AUTOSAR XML (schema 3.1.2)
package /Components/SWC_ExMGslT2
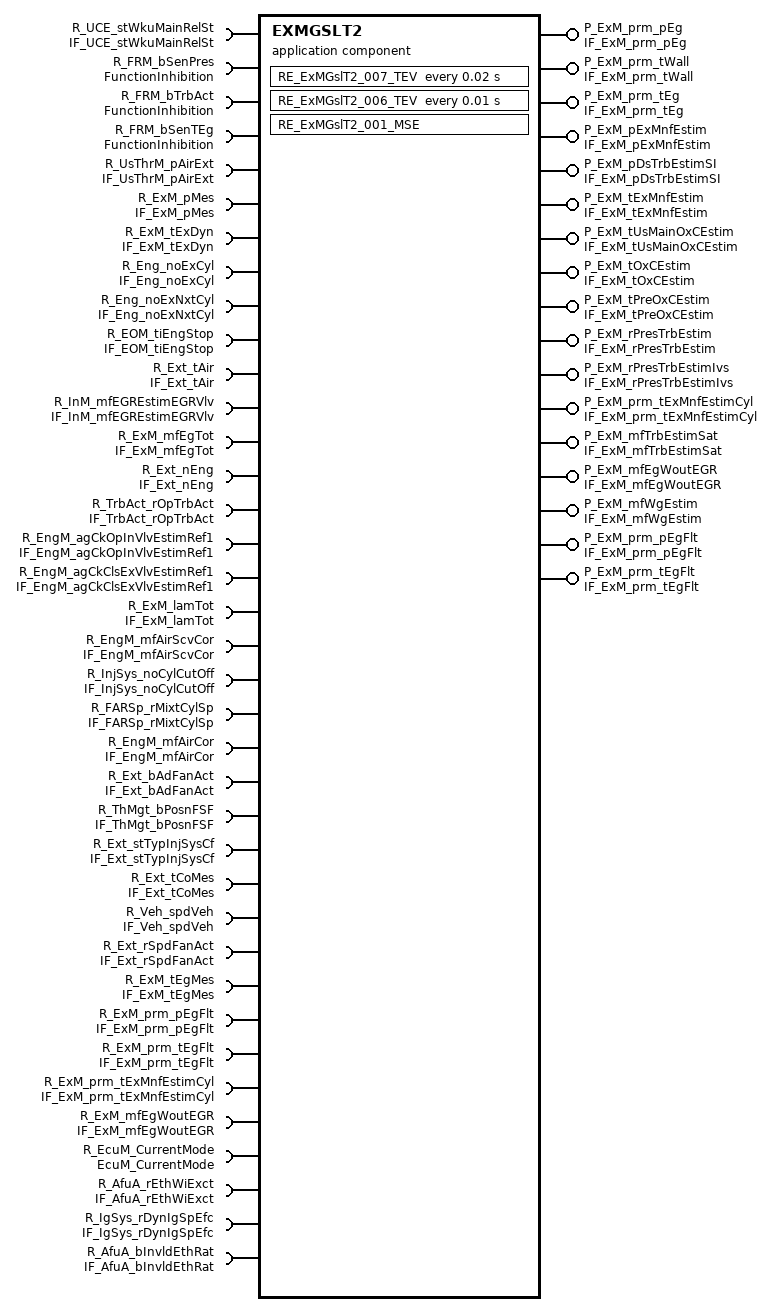
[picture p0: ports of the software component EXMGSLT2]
  application software component type EXMGSLT2  # ExMGslT2
    4 x require port:
      R_UCE_stWkuMainRelSt: required-interface=IF_UCE_stWkuMainRelSt
      R_FRM_bSenPres: required-interface=FunctionInhibition
      R_FRM_bTrbAct: required-interface=FunctionInhibition
      R_FRM_bSenTEg: required-interface=FunctionInhibition
    17 x provide port:
      P_ExM_prm_pEg: unqueued-sender-com-spec{data-element=ExM_prm_pEg, can-invalidate=false, init-value=rt_Array_UInt16_12InitValue}, provided-interface=IF_ExM_prm_pEg
      P_ExM_prm_tWall: unqueued-sender-com-spec{data-element=ExM_prm_tWall, can-invalidate=false, init-value=rt_Array_UInt16_12InitValue1}, provided-interface=IF_ExM_prm_tWall
      P_ExM_prm_tEg: unqueued-sender-com-spec{data-element=ExM_prm_tEg, can-invalidate=false, init-value=rt_Array_UInt16_12InitValue3}, provided-interface=IF_ExM_prm_tEg
      P_ExM_pExMnfEstim: unqueued-sender-com-spec{data-element=ExM_pExMnfEstim, can-invalidate=false, init-value=ConstantValue}, provided-interface=IF_ExM_pExMnfEstim
      P_ExM_pDsTrbEstimSI: unqueued-sender-com-spec{data-element=ExM_pDsTrbEstimSI, can-invalidate=false, init-value=ConstantValue5}, provided-interface=IF_ExM_pDsTrbEstimSI
      P_ExM_tExMnfEstim: unqueued-sender-com-spec{data-element=ExM_tExMnfEstim, can-invalidate=false, init-value=ConstantValue7}, provided-interface=IF_ExM_tExMnfEstim
      P_ExM_tUsMainOxCEstim: unqueued-sender-com-spec{data-element=ExM_tUsMainOxCEstim, can-invalidate=false, init-value=ConstantValue9}, provided-interface=IF_ExM_tUsMainOxCEstim
      P_ExM_tOxCEstim: unqueued-sender-com-spec{data-element=ExM_tOxCEstim, can-invalidate=false, init-value=SInt16InitValue}, provided-interface=IF_ExM_tOxCEstim
      P_ExM_tPreOxCEstim: unqueued-sender-com-spec{data-element=ExM_tPreOxCEstim, can-invalidate=false, init-value=SInt16InitValue11}, provided-interface=IF_ExM_tPreOxCEstim
      P_ExM_rPresTrbEstim: unqueued-sender-com-spec{data-element=ExM_rPresTrbEstim, can-invalidate=false, init-value=UInt16InitValue}, provided-interface=IF_ExM_rPresTrbEstim
      P_ExM_rPresTrbEstimIvs: unqueued-sender-com-spec{data-element=ExM_rPresTrbEstimIvs, can-invalidate=false, init-value=UInt16InitValue13}, provided-interface=IF_ExM_rPresTrbEstimIvs
      P_ExM_prm_tExMnfEstimCyl: unqueued-sender-com-spec{data-element=ExM_prm_tExMnfEstimCyl, can-invalidate=false, init-value=ArrayConstantValue}, provided-interface=IF_ExM_prm_tExMnfEstimCyl
      P_ExM_mfTrbEstimSat: unqueued-sender-com-spec{data-element=ExM_mfTrbEstimSat, can-invalidate=false, init-value=ConstantValue15}, provided-interface=IF_ExM_mfTrbEstimSat
      P_ExM_mfEgWoutEGR: unqueued-sender-com-spec{data-element=ExM_mfEgWoutEGR, can-invalidate=false, init-value=ConstantValue17}, provided-interface=IF_ExM_mfEgWoutEGR
      P_ExM_mfWgEstim: unqueued-sender-com-spec{data-element=ExM_mfWgEstim, can-invalidate=false, init-value=UInt16InitValue19}, provided-interface=IF_ExM_mfWgEstim
      P_ExM_prm_pEgFlt: unqueued-sender-com-spec{data-element=ExM_prm_pEgFlt, can-invalidate=false, init-value=rt_Array_UInt16_12InitValue21}, provided-interface=IF_ExM_prm_pEgFlt
      P_ExM_prm_tEgFlt: unqueued-sender-com-spec{data-element=ExM_prm_tEgFlt, can-invalidate=false, init-value=rt_Array_UInt16_12InitValue23}, provided-interface=IF_ExM_prm_tEgFlt
    33 x require port:
      R_UsThrM_pAirExt: unqueued-receiver-com-spec{data-element=UsThrM_pAirExt, init-value=ConstantValue25, resync-time=0}, required-interface=IF_UsThrM_pAirExt
      R_ExM_pMes: unqueued-receiver-com-spec{data-element=ExM_pMes, init-value=UInt16InitValue27, resync-time=0}, required-interface=IF_ExM_pMes
      R_ExM_tExDyn: unqueued-receiver-com-spec{data-element=ExM_tExDyn, init-value=ConstantValue29, resync-time=0}, required-interface=IF_ExM_tExDyn
      R_Eng_noExCyl: unqueued-receiver-com-spec{data-element=Eng_noExCyl, init-value=ConstantValue31, resync-time=0}, required-interface=IF_Eng_noExCyl
      R_Eng_noExNxtCyl: unqueued-receiver-com-spec{data-element=Eng_noExNxtCyl, init-value=ConstantValue33, resync-time=0}, required-interface=IF_Eng_noExNxtCyl
      R_EOM_tiEngStop: unqueued-receiver-com-spec{data-element=EOM_tiEngStop, init-value=ConstantValue35, resync-time=0}, required-interface=IF_EOM_tiEngStop
      R_Ext_tAir: unqueued-receiver-com-spec{data-element=Ext_tAir, init-value=ConstantValue37, resync-time=0}, required-interface=IF_Ext_tAir
      R_InM_mfEGREstimEGRVlv: unqueued-receiver-com-spec{data-element=InM_mfEGREstimEGRVlv, init-value=ConstantValue39, resync-time=0}, required-interface=IF_InM_mfEGREstimEGRVlv
      R_ExM_mfEgTot: unqueued-receiver-com-spec{data-element=ExM_mfEgTot, init-value=ConstantValue41, resync-time=0}, required-interface=IF_ExM_mfEgTot
      R_Ext_nEng: unqueued-receiver-com-spec{data-element=Ext_nEng, init-value=ConstantValue43, resync-time=0}, required-interface=IF_Ext_nEng
      R_TrbAct_rOpTrbAct: unqueued-receiver-com-spec{data-element=TrbAct_rOpTrbAct, init-value=UInt16InitValue45, resync-time=0}, required-interface=IF_TrbAct_rOpTrbAct
      R_EngM_agCkOpInVlvEstimRef1: unqueued-receiver-com-spec{data-element=EngM_agCkOpInVlvEstimRef1, init-value=ConstantValue47, resync-time=0}, required-interface=IF_EngM_agCkOpInVlvEstimRef1
      R_EngM_agCkClsExVlvEstimRef1: unqueued-receiver-com-spec{data-element=EngM_agCkClsExVlvEstimRef1, init-value=ConstantValue49, resync-time=0}, required-interface=IF_EngM_agCkClsExVlvEstimRef1
      R_ExM_lamTot: unqueued-receiver-com-spec{data-element=ExM_lamTot, init-value=ConstantValue51, resync-time=0}, required-interface=IF_ExM_lamTot
      R_EngM_mfAirScvCor: unqueued-receiver-com-spec{data-element=EngM_mfAirScvCor, init-value=ConstantValue53, resync-time=0}, required-interface=IF_EngM_mfAirScvCor
      R_InjSys_noCylCutOff: unqueued-receiver-com-spec{data-element=InjSys_noCylCutOff, init-value=ConstantValue55, resync-time=0}, required-interface=IF_InjSys_noCylCutOff
      R_FARSp_rMixtCylSp: unqueued-receiver-com-spec{data-element=FARSp_rMixtCylSp, init-value=ConstantValue57, resync-time=0}, required-interface=IF_FARSp_rMixtCylSp
      R_EngM_mfAirCor: unqueued-receiver-com-spec{data-element=EngM_mfAirCor, init-value=ConstantValue59, resync-time=0}, required-interface=IF_EngM_mfAirCor
      R_Ext_bAdFanAct: unqueued-receiver-com-spec{data-element=Ext_bAdFanAct, init-value=BooleanInitValue, resync-time=0}, required-interface=IF_Ext_bAdFanAct
      R_ThMgt_bPosnFSF: unqueued-receiver-com-spec{data-element=ThMgt_bPosnFSF, init-value=BooleanInitValue61, resync-time=0}, required-interface=IF_ThMgt_bPosnFSF
      R_Ext_stTypInjSysCf: unqueued-receiver-com-spec{data-element=Ext_stTypInjSysCf, init-value=UInt8InitValue, resync-time=0}, required-interface=IF_Ext_stTypInjSysCf
      R_Ext_tCoMes: unqueued-receiver-com-spec{data-element=Ext_tCoMes, init-value=ConstantValue63, resync-time=0}, required-interface=IF_Ext_tCoMes
      R_Veh_spdVeh: unqueued-receiver-com-spec{data-element=Veh_spdVeh, init-value=ConstantValue65, resync-time=0}, required-interface=IF_Veh_spdVeh
      R_Ext_rSpdFanAct: unqueued-receiver-com-spec{data-element=Ext_rSpdFanAct, init-value=UInt8InitValue67, resync-time=0}, required-interface=IF_Ext_rSpdFanAct
      R_ExM_tEgMes: unqueued-receiver-com-spec{data-element=ExM_tEgMes, init-value=UInt16InitValue69, resync-time=0}, required-interface=IF_ExM_tEgMes
      R_ExM_prm_pEgFlt: unqueued-receiver-com-spec{data-element=ExM_prm_pEgFlt, init-value=rt_Array_UInt16_12InitValue71, resync-time=0}, required-interface=IF_ExM_prm_pEgFlt
      R_ExM_prm_tEgFlt: unqueued-receiver-com-spec{data-element=ExM_prm_tEgFlt, init-value=rt_Array_UInt16_12InitValue73, resync-time=0}, required-interface=IF_ExM_prm_tEgFlt
      R_ExM_prm_tExMnfEstimCyl: unqueued-receiver-com-spec{data-element=ExM_prm_tExMnfEstimCyl, init-value=ArrayConstantValue, resync-time=0}, required-interface=IF_ExM_prm_tExMnfEstimCyl
      R_ExM_mfEgWoutEGR: unqueued-receiver-com-spec{data-element=ExM_mfEgWoutEGR, init-value=ConstantValue75, resync-time=0}, required-interface=IF_ExM_mfEgWoutEGR
      R_EcuM_CurrentMode: required-interface=EcuM_CurrentMode
      R_AfuA_rEthWiExct: unqueued-receiver-com-spec{data-element=AfuA_rEthWiExct, init-value=UInt8InitValue77, resync-time=0}, required-interface=IF_AfuA_rEthWiExct
      R_IgSys_rDynIgSpEfc: unqueued-receiver-com-spec{data-element=IgSys_rDynIgSpEfc, init-value=ConstantValue79, resync-time=0}, required-interface=IF_IgSys_rDynIgSpEfc
      R_AfuA_bInvldEthRat: unqueued-receiver-com-spec{data-element=AfuA_bInvldEthRat, init-value=ConstantValue1, resync-time=0}, required-interface=IF_AfuA_bInvldEthRat
  105 x constant specification:
    ArrayConstantValue
      value:
        array specification ArrayConstantValue: type=rt_Array_UInt16_6_m1
          6 x integer literal, all with type=DT_ExM_prm_tExMnfEstimCyl, value=0:
            Const
            Const{1..5}
    BooleanInitValue
      value:
        boolean literal BooleanInitValue: type=DT_Ext_bAdFanAct, value=false
    BooleanInitValue61
      value:
        boolean literal BooleanInitValue61: type=DT_ThMgt_bPosnFSF, value=false
    ConstantValue
      value:
        integer literal ConstantValue: type=DT_ExM_pExMnfEstim, value=0
    ConstantValue1
      value:
        boolean literal ConstantValue1: type=DT_AfuA_bInvldEthRat, value=false
    ConstantValue101
      value:
        real literal ConstantValue101: type=DT_ExM_prm_tWall_03_irv, value=0
    ConstantValue103
      value:
        real literal ConstantValue103: type=DT_ExM_prm_tWall_10_irv, value=0
    ConstantValue105
      value:
        real literal ConstantValue105: type=DT_ExM_prm_pEgRaw_07_irv, value=0
    ConstantValue109
      value:
        real literal ConstantValue109: type=DT_ExM_prm_tWall_08_irv, value=0
    ConstantValue115
      value:
        real literal ConstantValue115: type=DT_ExM_prm_pEgRaw_06_irv, value=0
    ConstantValue117
      value:
        real literal ConstantValue117: type=DT_ExM_prm_pEgRaw_05_irv, value=0
    ConstantValue119
      value:
        real literal ConstantValue119: type=DT_ExM_prm_tEgRaw_03_irv, value=0
    ConstantValue121
      value:
        real literal ConstantValue121: type=DT_ExM_prm_pEgRaw_03_irv, value=0
    ConstantValue123
      value:
        real literal ConstantValue123: type=DT_ExM_prm_tWall_09_irv, value=0
    ConstantValue125
      value:
        real literal ConstantValue125: type=DT_ExM_prm_tWall_01_irv, value=0
    ConstantValue127
      value:
        real literal ConstantValue127: type=DT_ExM_prm_tWall_06_irv, value=0
    ConstantValue129
      value:
        real literal ConstantValue129: type=DT_ExM_prm_tEgOxC_01_irv, value=0
    ConstantValue139
      value:
        real literal ConstantValue139: type=DT_ExM_mfWgEstim_irv, value=0
    ConstantValue141
      value:
        real literal ConstantValue141: type=DT_ExM_prm_tWall_04_irv, value=0
    ConstantValue145
      value:
        real literal ConstantValue145: type=DT_ExM_prm_tWall_11_irv, value=0
    ConstantValue147
      value:
        real literal ConstantValue147: type=DT_ExM_prm_tEgRaw_07_irv, value=0
    ConstantValue15
      value:
        integer literal ConstantValue15: type=DT_ExM_mfTrbEstimSat, value=0
    ConstantValue153
      value:
        real literal ConstantValue153: type=DT_ExM_prm_pEgRaw_01_irv, value=0
    ConstantValue155
      value:
        real literal ConstantValue155: type=DT_ExM_prm_pEgRaw_12_irv, value=0
    ConstantValue157
      value:
        real literal ConstantValue157: type=DT_ExM_prm_tEgRaw_06_irv, value=0
    ConstantValue159
      value:
        real literal ConstantValue159: type=DT_ExM_prm_tEgRaw_05_irv, value=0
    ConstantValue161
      value:
        real literal ConstantValue161: type=DT_ExM_prm_tWall_12_irv, value=0
    ConstantValue167
      value:
        real literal ConstantValue167: type=DT_ExM_prm_tEgRaw_04_irv, value=0
    ConstantValue169
      value:
        real literal ConstantValue169: type=DT_ExM_prm_tEgRaw_08_irv, value=0
    ConstantValue17
      value:
        integer literal ConstantValue17: type=DT_ExM_mfEgWoutEGR, value=0
    ConstantValue171
      value:
        real literal ConstantValue171: type=DT_ExM_mfTrbEstimSat_irv, value=0
    ConstantValue173
      value:
        real literal ConstantValue173: type=DT_ExM_prm_pEgRaw_08_irv, value=0
    ConstantValue177
      value:
        real literal ConstantValue177: type=DT_ExM_prm_tWall_02_irv, value=0
    ConstantValue179
      value:
        real literal ConstantValue179: type=DT_ExM_prm_tEgRaw_01_irv, value=0
    ConstantValue181
      value:
        real literal ConstantValue181: type=DT_ExM_prm_pEgRaw_11_irv, value=0
    ConstantValue185
      value:
        real literal ConstantValue185: type=DT_ExM_prm_tEgRaw_11_irv, value=0
    ConstantValue187
      value:
        real literal ConstantValue187: type=DT_ExM_prm_tEgRaw_02_irv, value=0
    ConstantValue189
      value:
        real literal ConstantValue189: type=DT_ExM_prm_pEgRaw_09_irv, value=0
    ConstantValue191
      value:
        real literal ConstantValue191: type=DT_ExM_prm_tEgOxC_02_irv, value=0
    ConstantValue193
      value:
        real literal ConstantValue193: type=DT_ExM_prm_tEgRaw_09_irv, value=0
    ConstantValue25
      value:
        integer literal ConstantValue25: type=DT_UsThrM_pAirExt, value=0
    ConstantValue29
      value:
        integer literal ConstantValue29: type=DT_ExM_tExDyn, value=0
    ConstantValue31
      value:
        integer literal ConstantValue31: type=DT_Eng_noExCyl, value=1
    ConstantValue33
      value:
        integer literal ConstantValue33: type=DT_Eng_noExNxtCyl, value=1
    ConstantValue35
      value:
        integer literal ConstantValue35: type=DT_EOM_tiEngStop, value=864000
    ConstantValue37
      value:
        integer literal ConstantValue37: type=DT_Ext_tAir, value=20
    ConstantValue39
      value:
        integer literal ConstantValue39: type=DT_InM_mfEGREstimEGRVlv, value=0
    ConstantValue41
      value:
        integer literal ConstantValue41: type=DT_ExM_mfEgTot, value=0
    ConstantValue43
      value:
        integer literal ConstantValue43: type=DT_Ext_nEng, value=0
    ConstantValue47
      value:
        integer literal ConstantValue47: type=DT_EngM_agCkOpInVlvEstimRef1, value=0
    ConstantValue49
      value:
        integer literal ConstantValue49: type=DT_EngM_agCkClsExVlvEstimRef1, value=0
    ConstantValue5
      value:
        integer literal ConstantValue5: type=DT_ExM_pDsTrbEstimSI, value=0
    ConstantValue51
      value:
        integer literal ConstantValue51: type=DT_ExM_lamTot, value=8192
    ConstantValue53
      value:
        integer literal ConstantValue53: type=DT_EngM_mfAirScvCor, value=0
    ConstantValue55
      value:
        integer literal ConstantValue55: type=DT_InjSys_noCylCutOff, value=0
    ConstantValue57
      value:
        integer literal ConstantValue57: type=DT_FARSp_rMixtCylSp, value=4096
    ConstantValue59
      value:
        integer literal ConstantValue59: type=DT_EngM_mfAirCor, value=0
    ConstantValue63
      value:
        integer literal ConstantValue63: type=DT_Ext_tCoMes, value=20
    ConstantValue65
      value:
        integer literal ConstantValue65: type=DT_Veh_spdVeh, value=0
    ConstantValue7
      value:
        integer literal ConstantValue7: type=DT_ExM_tExMnfEstim, value=4800
    ConstantValue75
      value:
        integer literal ConstantValue75: type=DT_ExM_mfEgWoutEGR, value=0
    ConstantValue79
      value:
        integer literal ConstantValue79: type=DT_IgSys_rDynIgSpEfc, value=0
    ConstantValue81
      value:
        real literal ConstantValue81: type=DT_ExM_prm_tEgOxC_03_irv, value=0
    ConstantValue83
      value:
        real literal ConstantValue83: type=DT_ExM_prm_tEgRaw_10_irv, value=0
    ConstantValue85
      value:
        real literal ConstantValue85: type=DT_ExM_prm_tWall_07_irv, value=0
    ConstantValue87
      value:
        real literal ConstantValue87: type=DT_ExM_prm_tWall_05_irv, value=0
    ConstantValue89
      value:
        real literal ConstantValue89: type=DT_ExM_prm_pEgRaw_10_irv, value=0
    ConstantValue9
      value:
        integer literal ConstantValue9: type=DT_ExM_tUsMainOxCEstim, value=0
    ConstantValue91
      value:
        real literal ConstantValue91: type=DT_ExM_prm_tEgRaw_12_irv, value=0
    ConstantValue93
      value:
        real literal ConstantValue93: type=DT_ExM_prm_pEgRaw_04_irv, value=0
    ConstantValue99
      value:
        real literal ConstantValue99: type=DT_ExM_prm_pEgRaw_02_irv, value=0
    rt_Array_UInt16_12InitValue
      value:
        array specification rt_Array_UInt16_12InitValue: type=rt_Array_UInt16_12_m2
          12 x integer literal, all with type=DT_ExM_prm_pEg, value=0:
            UInt16_{1..12}
    rt_Array_UInt16_12InitValue1
      value:
        array specification rt_Array_UInt16_12InitValue1: type=rt_Array_UInt16_12_m1
          12 x integer literal, all with type=DT_ExM_prm_tWall, value=0:
            UInt16_{1..12}
    rt_Array_UInt16_12InitValue21
      value:
        array specification rt_Array_UInt16_12InitValue21: type=rt_Array_UInt16_12_m3
          12 x integer literal, all with type=DT_ExM_prm_pEgFlt, value=0:
            UInt16_{1..12}
    rt_Array_UInt16_12InitValue23
      value:
        array specification rt_Array_UInt16_12InitValue23: type=rt_Array_UInt16_12_m5
          12 x integer literal, all with type=DT_ExM_prm_tEgFlt, value=0:
            UInt16_{1..12}
    rt_Array_UInt16_12InitValue3
      value:
        array specification rt_Array_UInt16_12InitValue3: type=rt_Array_UInt16_12_m0
          12 x integer literal, all with type=DT_ExM_prm_tEg, value=0:
            UInt16_{1..12}
    rt_Array_UInt16_12InitValue71
      value:
        array specification rt_Array_UInt16_12InitValue71: type=rt_Array_UInt16_12_m3
          12 x integer literal, all with type=DT_ExM_prm_pEgFlt, value=0:
            UInt16_{1..12}
    rt_Array_UInt16_12InitValue73
      value:
        array specification rt_Array_UInt16_12InitValue73: type=rt_Array_UInt16_12_m5
          12 x integer literal, all with type=DT_ExM_prm_tEgFlt, value=0:
            UInt16_{1..12}
    SInt16InitValue
      value:
        integer literal SInt16InitValue: type=DT_ExM_tOxCEstim, value=-55
    SInt16InitValue11
      value:
        integer literal SInt16InitValue11: type=DT_ExM_tPreOxCEstim, value=-55
    UInt16InitValue
      value:
        integer literal UInt16InitValue: type=DT_ExM_rPresTrbEstim, value=0
    UInt16InitValue13
      value:
        integer literal UInt16InitValue13: type=DT_ExM_rPresTrbEstimIvs, value=0
    UInt16InitValue19
      value:
        integer literal UInt16InitValue19: type=DT_ExM_mfWgEstim, value=0
    UInt16InitValue27
      value:
        integer literal UInt16InitValue27: type=DT_ExM_pMes, value=12662
    UInt16InitValue45
      value:
        integer literal UInt16InitValue45: type=DT_TrbAct_rOpTrbAct, value=0
    UInt16InitValue69
      value:
        integer literal UInt16InitValue69: type=DT_ExM_tEgMes, value=15264
    UInt8InitValue
      value:
        integer literal UInt8InitValue: type=DT_Ext_stTypInjSysCf, value=1
    UInt8InitValue107
      value:
        integer literal UInt8InitValue107: type=DT_ExM_prm_stElement_01_irv, value=0
    UInt8InitValue111
      value:
        integer literal UInt8InitValue111: type=DT_ExM_prm_stNbTypElement_08_irv, value=0
    UInt8InitValue113
      value:
        integer literal UInt8InitValue113: type=DT_ExM_prm_stNbTypElement_01_irv, value=0
    UInt8InitValue131
      value:
        integer literal UInt8InitValue131: type=DT_ExM_prm_stNbTypElement_05_irv, value=0
    UInt8InitValue133
      value:
        integer literal UInt8InitValue133: type=DT_ExM_prm_stNbTypElement_02_irv, value=0
    UInt8InitValue135
      value:
        integer literal UInt8InitValue135: type=DT_ExM_prm_stNbTypElement_06_irv, value=0
    UInt8InitValue137
      value:
        integer literal UInt8InitValue137: type=DT_ExM_prm_stElement_02_irv, value=0
    UInt8InitValue143
      value:
        integer literal UInt8InitValue143: type=DT_ExM_prm_stNbTypElement_03_irv, value=0
    UInt8InitValue149
      value:
        integer literal UInt8InitValue149: type=DT_ExM_prm_stElement_08_irv, value=0
    UInt8InitValue151
      value:
        integer literal UInt8InitValue151: type=DT_ExM_prm_stElement_04_irv, value=0
    UInt8InitValue163
      value:
        integer literal UInt8InitValue163: type=DT_ExM_prm_stElement_06_irv, value=0
    UInt8InitValue165
      value:
        integer literal UInt8InitValue165: type=DT_ExM_prm_stNbTypElement_07_irv, value=0
    UInt8InitValue175
      value:
        integer literal UInt8InitValue175: type=DT_ExM_prm_stElement_07_irv, value=0
    UInt8InitValue183
      value:
        integer literal UInt8InitValue183: type=DT_ExM_prm_stNbTypElement_04_irv, value=0
    UInt8InitValue67
      value:
        integer literal UInt8InitValue67: type=DT_Ext_rSpdFanAct, value=0
    UInt8InitValue77
      value:
        integer literal UInt8InitValue77: type=DT_AfuA_rEthWiExct, value=0
    UInt8InitValue95
      value:
        integer literal UInt8InitValue95: type=DT_ExM_prm_stElement_03_irv, value=0
    UInt8InitValue97
      value:
        integer literal UInt8InitValue97: type=DT_ExM_prm_stElement_05_irv, value=0
  internal behavior IB_ExMGslT2: component=EXMGSLT2
    timing event EV_ExMGslT2_007_TEV: mode-dependency=dependent-on-mode=[R_UCE_stWkuMainRelSt.RCD_stWkuMainRelSt.PreMainWakeUp, R_UCE_stWkuMainRelSt.RCD_stWkuMainRelSt.PostMainWakeUp, R_UCE_stWkuMainRelSt.RCD_stWkuMainRelSt.Invalid], start-on-event=RE_ExMGslT2_007_TEV, period=0.02
    timing event EV_ExMGslT2_006_TEV: mode-dependency=dependent-on-mode=[R_UCE_stWkuMainRelSt.RCD_stWkuMainRelSt.PreMainWakeUp, R_UCE_stWkuMainRelSt.RCD_stWkuMainRelSt.PostMainWakeUp, R_UCE_stWkuMainRelSt.RCD_stWkuMainRelSt.Invalid], start-on-event=RE_ExMGslT2_006_TEV, period=0.01
    mode switch event EV_ExMGslT2_001_MSE: start-on-event=RE_ExMGslT2_001_MSE, activation=ENTRY, mode=R_EcuM_CurrentMode.currentMode.RUN
    57 x inter runnable variable, all with sw-calibration-access=READ-WRITE, communication-approach=EXPLICIT:
      ExM_prm_tWall_05_irv: type=DT_ExM_prm_tWall_05_irv, init-value=ConstantValue87
      ExM_prm_tWall_02_irv: type=DT_ExM_prm_tWall_02_irv, init-value=ConstantValue177
      ExM_prm_pEgRaw_11_irv: type=DT_ExM_prm_pEgRaw_11_irv, init-value=ConstantValue181
      ExM_prm_stNbTypElement_05_irv: type=DT_ExM_prm_stNbTypElement_05_irv, init-value=UInt8InitValue131
      ExM_prm_stNbTypElement_02_irv: type=DT_ExM_prm_stNbTypElement_02_irv, init-value=UInt8InitValue133
      ExM_mfWgEstim_irv: type=DT_ExM_mfWgEstim_irv, init-value=ConstantValue139
      ExM_prm_pEgRaw_08_irv: type=DT_ExM_prm_pEgRaw_08_irv, init-value=ConstantValue173
      ExM_prm_tEgRaw_03_irv: type=DT_ExM_prm_tEgRaw_03_irv, init-value=ConstantValue119
      ExM_prm_pEgRaw_12_irv: type=DT_ExM_prm_pEgRaw_12_irv, init-value=ConstantValue155
      ExM_prm_tWall_09_irv: type=DT_ExM_prm_tWall_09_irv, init-value=ConstantValue123
      ExM_mfTrbEstimSat_irv: type=DT_ExM_mfTrbEstimSat_irv, init-value=ConstantValue171
      ExM_prm_tWall_01_irv: type=DT_ExM_prm_tWall_01_irv, init-value=ConstantValue125
      ExM_prm_stElement_02_irv: type=DT_ExM_prm_stElement_02_irv, init-value=UInt8InitValue137
      ExM_prm_stNbTypElement_06_irv: type=DT_ExM_prm_stNbTypElement_06_irv, init-value=UInt8InitValue135
      ExM_prm_tEgRaw_10_irv: type=DT_ExM_prm_tEgRaw_10_irv, init-value=ConstantValue83
      ExM_prm_tWall_12_irv: type=DT_ExM_prm_tWall_12_irv, init-value=ConstantValue161
      ExM_prm_tEgOxC_02_irv: type=DT_ExM_prm_tEgOxC_02_irv, init-value=ConstantValue191
      ExM_prm_tEgRaw_04_irv: type=DT_ExM_prm_tEgRaw_04_irv, init-value=ConstantValue167
      ExM_prm_stElement_04_irv: type=DT_ExM_prm_stElement_04_irv, init-value=UInt8InitValue151
      ExM_prm_tEgRaw_09_irv: type=DT_ExM_prm_tEgRaw_09_irv, init-value=ConstantValue193
      ExM_prm_stElement_05_irv: type=DT_ExM_prm_stElement_05_irv, init-value=UInt8InitValue97
      ExM_prm_stElement_07_irv: type=DT_ExM_prm_stElement_07_irv, init-value=UInt8InitValue175
      ExM_prm_tWall_04_irv: type=DT_ExM_prm_tWall_04_irv, init-value=ConstantValue141
      ExM_prm_stElement_01_irv: type=DT_ExM_prm_stElement_01_irv, init-value=UInt8InitValue107
      ExM_prm_tEgRaw_07_irv: type=DT_ExM_prm_tEgRaw_07_irv, init-value=ConstantValue147
      ExM_prm_tWall_07_irv: type=DT_ExM_prm_tWall_07_irv, init-value=ConstantValue85
      ExM_prm_stNbTypElement_04_irv: type=DT_ExM_prm_stNbTypElement_04_irv, init-value=UInt8InitValue183
      ExM_prm_tEgRaw_01_irv: type=DT_ExM_prm_tEgRaw_01_irv, init-value=ConstantValue179
      ExM_prm_stElement_03_irv: type=DT_ExM_prm_stElement_03_irv, init-value=UInt8InitValue95
      ExM_prm_tEgRaw_05_irv: type=DT_ExM_prm_tEgRaw_05_irv, init-value=ConstantValue159
      ExM_prm_pEgRaw_06_irv: type=DT_ExM_prm_pEgRaw_06_irv, init-value=ConstantValue115
      ExM_prm_pEgRaw_09_irv: type=DT_ExM_prm_pEgRaw_09_irv, init-value=ConstantValue189
      ExM_prm_tWall_06_irv: type=DT_ExM_prm_tWall_06_irv, init-value=ConstantValue127
      ExM_prm_stNbTypElement_08_irv: type=DT_ExM_prm_stNbTypElement_08_irv, init-value=UInt8InitValue111
      ExM_prm_stElement_06_irv: type=DT_ExM_prm_stElement_06_irv, init-value=UInt8InitValue163
      ExM_prm_pEgRaw_04_irv: type=DT_ExM_prm_pEgRaw_04_irv, init-value=ConstantValue93
      ExM_prm_tEgRaw_06_irv: type=DT_ExM_prm_tEgRaw_06_irv, init-value=ConstantValue157
      ExM_prm_tWall_11_irv: type=DT_ExM_prm_tWall_11_irv, init-value=ConstantValue145
      ExM_prm_tEgRaw_12_irv: type=DT_ExM_prm_tEgRaw_12_irv, init-value=ConstantValue91
      ExM_prm_stNbTypElement_07_irv: type=DT_ExM_prm_stNbTypElement_07_irv, init-value=UInt8InitValue165
      ExM_prm_tEgRaw_11_irv: type=DT_ExM_prm_tEgRaw_11_irv, init-value=ConstantValue185
      ExM_prm_tEgRaw_08_irv: type=DT_ExM_prm_tEgRaw_08_irv, init-value=ConstantValue169
      ExM_prm_pEgRaw_02_irv: type=DT_ExM_prm_pEgRaw_02_irv, init-value=ConstantValue99
      ExM_prm_stNbTypElement_01_irv: type=DT_ExM_prm_stNbTypElement_01_irv, init-value=UInt8InitValue113
      ExM_prm_tWall_10_irv: type=DT_ExM_prm_tWall_10_irv, init-value=ConstantValue103
      ExM_prm_tEgOxC_03_irv: type=DT_ExM_prm_tEgOxC_03_irv, init-value=ConstantValue81
      ExM_prm_tWall_03_irv: type=DT_ExM_prm_tWall_03_irv, init-value=ConstantValue101
      ExM_prm_stElement_08_irv: type=DT_ExM_prm_stElement_08_irv, init-value=UInt8InitValue149
      ExM_prm_stNbTypElement_03_irv: type=DT_ExM_prm_stNbTypElement_03_irv, init-value=UInt8InitValue143
      ExM_prm_tEgRaw_02_irv: type=DT_ExM_prm_tEgRaw_02_irv, init-value=ConstantValue187
      ExM_prm_pEgRaw_01_irv: type=DT_ExM_prm_pEgRaw_01_irv, init-value=ConstantValue153
      ExM_prm_pEgRaw_10_irv: type=DT_ExM_prm_pEgRaw_10_irv, init-value=ConstantValue89
      ExM_prm_pEgRaw_05_irv: type=DT_ExM_prm_pEgRaw_05_irv, init-value=ConstantValue117
      ExM_prm_pEgRaw_07_irv: type=DT_ExM_prm_pEgRaw_07_irv, init-value=ConstantValue105
      ExM_prm_pEgRaw_03_irv: type=DT_ExM_prm_pEgRaw_03_irv, init-value=ConstantValue121
      ExM_prm_tEgOxC_01_irv: type=DT_ExM_prm_tEgOxC_01_irv, init-value=ConstantValue129
      ExM_prm_tWall_08_irv: type=DT_ExM_prm_tWall_08_irv, init-value=ConstantValue109
    runnable RE_ExMGslT2_001_MSE: written-variable=[ExM_prm_tWall_07_irv, ExM_prm_stNbTypElement_07_irv, ExM_prm_tEgRaw_05_irv, ExM_prm_pEgRaw_04_irv, ExM_prm_stNbTypElement_04_irv, ExM_prm_pEgRaw_09_irv, ExM_prm_tWall_08_irv, ExM_prm_tEgRaw_02_irv, ExM_prm_stNbTypElement_01_irv, ExM_prm_tEgRaw_01_irv, ExM_prm_tWall_11_irv, ExM_prm_tEgOxC_03_irv, ExM_prm_stElement_05_irv, ExM_prm_tEgRaw_09_irv, ExM_prm_stElement_08_irv, ExM_mfTrbEstimSat_irv, ExM_prm_tEgRaw_03_irv, ExM_prm_tEgRaw_11_irv, ExM_prm_pEgRaw_10_irv, ExM_prm_pEgRaw_11_irv, ExM_prm_tEgOxC_02_irv, ExM_prm_stElement_04_irv, ExM_prm_stElement_06_irv, ExM_prm_tWall_04_irv, ExM_prm_tWall_09_irv, ExM_prm_pEgRaw_02_irv, ExM_mfWgEstim_irv, ExM_prm_tEgRaw_07_irv, ExM_prm_stElement_02_irv, ExM_prm_stNbTypElement_06_irv, ExM_prm_tEgRaw_12_irv, ExM_prm_stNbTypElement_08_irv, ExM_prm_pEgRaw_03_irv, ExM_prm_pEgRaw_08_irv, ExM_prm_tWall_01_irv, ExM_prm_stElement_01_irv, ExM_prm_tWall_05_irv, ExM_prm_pEgRaw_12_irv, ExM_prm_stNbTypElement_02_irv, ExM_prm_pEgRaw_07_irv, ExM_prm_stNbTypElement_03_irv, ExM_prm_pEgRaw_05_irv, ExM_prm_tWall_12_irv, ExM_prm_stElement_07_irv, ExM_prm_stElement_03_irv, ExM_prm_tEgRaw_04_irv, ExM_prm_tEgRaw_10_irv, ExM_prm_tEgRaw_06_irv, ExM_prm_tEgRaw_08_irv, ExM_prm_stNbTypElement_05_irv, ExM_prm_tWall_02_irv, ExM_prm_pEgRaw_06_irv, ExM_prm_tEgOxC_01_irv, ExM_prm_tWall_03_irv, ExM_prm_pEgRaw_01_irv, ExM_prm_tWall_06_irv, ExM_prm_tWall_10_irv]
      data receive point dr_Ext_tAir: data-element=R_Ext_tAir.Ext_tAir
      data receive point dr_EOM_tiEngStop: data-element=R_EOM_tiEngStop.EOM_tiEngStop
      data receive point dr_UsThrM_pAirExt: data-element=R_UsThrM_pAirExt.UsThrM_pAirExt
      17 x data send point:
        ds_ExM_mfWgEstim: data-element=P_ExM_mfWgEstim.ExM_mfWgEstim
        ds_ExM_prm_tExMnfEstimCyl: data-element=P_ExM_prm_tExMnfEstimCyl.ExM_prm_tExMnfEstimCyl
        ds_ExM_rPresTrbEstimIvs: data-element=P_ExM_rPresTrbEstimIvs.ExM_rPresTrbEstimIvs
        ds_ExM_tPreOxCEstim: data-element=P_ExM_tPreOxCEstim.ExM_tPreOxCEstim
        ds_ExM_tOxCEstim: data-element=P_ExM_tOxCEstim.ExM_tOxCEstim
        ds_ExM_prm_pEgFlt: data-element=P_ExM_prm_pEgFlt.ExM_prm_pEgFlt
        ds_ExM_prm_tEg: data-element=P_ExM_prm_tEg.ExM_prm_tEg
        ds_ExM_prm_tWall: data-element=P_ExM_prm_tWall.ExM_prm_tWall
        ds_ExM_pExMnfEstim: data-element=P_ExM_pExMnfEstim.ExM_pExMnfEstim
        ds_ExM_mfTrbEstimSat: data-element=P_ExM_mfTrbEstimSat.ExM_mfTrbEstimSat
        ds_ExM_prm_tEgFlt: data-element=P_ExM_prm_tEgFlt.ExM_prm_tEgFlt
        ds_ExM_tExMnfEstim: data-element=P_ExM_tExMnfEstim.ExM_tExMnfEstim
        ds_ExM_pDsTrbEstimSI: data-element=P_ExM_pDsTrbEstimSI.ExM_pDsTrbEstimSI
        ds_ExM_tUsMainOxCEstim: data-element=P_ExM_tUsMainOxCEstim.ExM_tUsMainOxCEstim
        ds_ExM_mfEgWoutEGR: data-element=P_ExM_mfEgWoutEGR.ExM_mfEgWoutEGR
        ds_ExM_rPresTrbEstim: data-element=P_ExM_rPresTrbEstim.ExM_rPresTrbEstim
        ds_ExM_prm_pEg: data-element=P_ExM_prm_pEg.ExM_prm_pEg
    runnable RE_ExMGslT2_007_TEV: read-variable=[ExM_prm_stNbTypElement_03_irv, ExM_prm_tEgRaw_12_irv, ExM_prm_stElement_06_irv, ExM_prm_pEgRaw_02_irv, ExM_prm_tWall_07_irv, ExM_prm_stNbTypElement_07_irv, ExM_prm_tEgOxC_03_irv, ExM_prm_pEgRaw_05_irv, ExM_prm_stNbTypElement_05_irv, ExM_prm_stElement_01_irv, ExM_prm_pEgRaw_09_irv, ExM_prm_tEgRaw_01_irv, ExM_prm_pEgRaw_11_irv, ExM_prm_pEgRaw_08_irv, ExM_prm_tWall_06_irv, ExM_prm_pEgRaw_12_irv, ExM_prm_tEgRaw_02_irv, ExM_prm_stNbTypElement_08_irv, ExM_prm_tEgRaw_05_irv, ExM_prm_tWall_11_irv, ExM_mfWgEstim_irv, ExM_prm_tEgRaw_07_irv, ExM_prm_tWall_04_irv, ExM_prm_tEgRaw_04_irv, ExM_prm_pEgRaw_01_irv, ExM_prm_pEgRaw_04_irv, ExM_prm_stNbTypElement_06_irv, ExM_prm_stNbTypElement_04_irv, ExM_prm_stElement_05_irv, ExM_prm_tWall_01_irv, ExM_prm_tEgOxC_02_irv, ExM_prm_stNbTypElement_01_irv, ExM_prm_tWall_08_irv, ExM_prm_stElement_08_irv, ExM_prm_tEgRaw_08_irv, ExM_prm_stElement_07_irv, ExM_prm_tEgRaw_11_irv, ExM_prm_pEgRaw_10_irv, ExM_prm_stElement_02_irv, ExM_prm_tEgOxC_01_irv, ExM_mfTrbEstimSat_irv, ExM_prm_tEgRaw_06_irv, ExM_prm_stNbTypElement_02_irv, ExM_prm_tWall_03_irv, ExM_prm_pEgRaw_03_irv, ExM_prm_tWall_10_irv, ExM_prm_tWall_05_irv, ExM_prm_tWall_02_irv, ExM_prm_tEgRaw_10_irv, ExM_prm_tWall_12_irv, ExM_prm_pEgRaw_06_irv, ExM_prm_stElement_03_irv, ExM_prm_pEgRaw_07_irv, ExM_prm_tWall_09_irv, ExM_prm_tEgRaw_09_irv, ExM_prm_stElement_04_irv, ExM_prm_tEgRaw_03_irv], written-variable=[ExM_prm_tEgRaw_12_irv, ExM_prm_tWall_07_irv, ExM_prm_tEgOxC_03_irv, ExM_prm_tEgRaw_01_irv, ExM_prm_tWall_06_irv, ExM_prm_tEgRaw_02_irv, ExM_prm_tEgRaw_05_irv, ExM_prm_tWall_11_irv, ExM_prm_tEgRaw_07_irv, ExM_prm_tWall_04_irv, ExM_prm_tEgRaw_04_irv, ExM_prm_tWall_01_irv, ExM_prm_tEgOxC_02_irv, ExM_prm_tWall_08_irv, ExM_prm_tEgRaw_08_irv, ExM_prm_tEgRaw_11_irv, ExM_prm_tEgOxC_01_irv, ExM_prm_tEgRaw_06_irv, ExM_prm_tWall_03_irv, ExM_prm_tWall_10_irv, ExM_prm_tWall_05_irv, ExM_prm_tWall_02_irv, ExM_prm_tEgRaw_10_irv, ExM_prm_tWall_12_irv, ExM_prm_tWall_09_irv, ExM_prm_tEgRaw_09_irv, ExM_prm_tEgRaw_03_irv]
      23 x data receive point:
        dr_ExM_lamTot: data-element=R_ExM_lamTot.ExM_lamTot
        dr_ExM_tExDyn: data-element=R_ExM_tExDyn.ExM_tExDyn
        dr_Eng_noExCyl: data-element=R_Eng_noExCyl.Eng_noExCyl
        dr_ExM_prm_tEgFlt: data-element=R_ExM_prm_tEgFlt.ExM_prm_tEgFlt
        dr_ThMgt_bPosnFSF: data-element=R_ThMgt_bPosnFSF.ThMgt_bPosnFSF
        dr_IgSys_rDynIgSpEfc: data-element=R_IgSys_rDynIgSpEfc.IgSys_rDynIgSpEfc
        dr_ExM_tEgMes: data-element=R_ExM_tEgMes.ExM_tEgMes
        dr_Ext_tCoMes: data-element=R_Ext_tCoMes.Ext_tCoMes
        dr_ExM_prm_tExMnfEstimCyl: data-element=R_ExM_prm_tExMnfEstimCyl.ExM_prm_tExMnfEstimCyl
        dr_Ext_bAdFanAct: data-element=R_Ext_bAdFanAct.Ext_bAdFanAct
        dr_EngM_mfAirCor: data-element=R_EngM_mfAirCor.EngM_mfAirCor
        dr_Ext_tAir: data-element=R_Ext_tAir.Ext_tAir
        dr_Ext_nEng: data-element=R_Ext_nEng.Ext_nEng
        dr_Eng_noExNxtCyl: data-element=R_Eng_noExNxtCyl.Eng_noExNxtCyl
        dr_AfuA_bInvldEthRat: data-element=R_AfuA_bInvldEthRat.AfuA_bInvldEthRat
        dr_EngM_mfAirScvCor: data-element=R_EngM_mfAirScvCor.EngM_mfAirScvCor
        dr_FARSp_rMixtCylSp: data-element=R_FARSp_rMixtCylSp.FARSp_rMixtCylSp
        dr_Veh_spdVeh: data-element=R_Veh_spdVeh.Veh_spdVeh
        dr_Ext_stTypInjSysCf: data-element=R_Ext_stTypInjSysCf.Ext_stTypInjSysCf
        dr_ExM_mfEgWoutEGR: data-element=R_ExM_mfEgWoutEGR.ExM_mfEgWoutEGR
        dr_Ext_rSpdFanAct: data-element=R_Ext_rSpdFanAct.Ext_rSpdFanAct
        dr_InjSys_noCylCutOff: data-element=R_InjSys_noCylCutOff.InjSys_noCylCutOff
        dr_AfuA_rEthWiExct: data-element=R_AfuA_rEthWiExct.AfuA_rEthWiExct
      8 x data send point:
        ds_ExM_tUsMainOxCEstim: data-element=P_ExM_tUsMainOxCEstim.ExM_tUsMainOxCEstim
        ds_ExM_prm_tEg: data-element=P_ExM_prm_tEg.ExM_prm_tEg
        ds_ExM_tOxCEstim: data-element=P_ExM_tOxCEstim.ExM_tOxCEstim
        ds_ExM_prm_tEgFlt: data-element=P_ExM_prm_tEgFlt.ExM_prm_tEgFlt
        ds_ExM_tPreOxCEstim: data-element=P_ExM_tPreOxCEstim.ExM_tPreOxCEstim
        ds_ExM_tExMnfEstim: data-element=P_ExM_tExMnfEstim.ExM_tExMnfEstim
        ds_ExM_prm_tWall: data-element=P_ExM_prm_tWall.ExM_prm_tWall
        ds_ExM_prm_tExMnfEstimCyl: data-element=P_ExM_prm_tExMnfEstimCyl.ExM_prm_tExMnfEstimCyl
      sync call ssp_FRM_bSenTEg: operation=R_FRM_bSenTEg.GetFunctionPermission
    runnable RE_ExMGslT2_006_TEV: read-variable=[ExM_prm_stElement_04_irv, ExM_prm_stNbTypElement_06_irv, ExM_prm_pEgRaw_06_irv, ExM_prm_stNbTypElement_02_irv, ExM_prm_stElement_05_irv, ExM_prm_pEgRaw_11_irv, ExM_prm_tEgRaw_02_irv, ExM_prm_stNbTypElement_05_irv, ExM_prm_stNbTypElement_01_irv, ExM_prm_stElement_06_irv, ExM_mfWgEstim_irv, ExM_prm_tEgRaw_05_irv, ExM_prm_stElement_01_irv, ExM_prm_tEgRaw_11_irv, ExM_prm_tEgRaw_04_irv, ExM_prm_tEgRaw_01_irv, ExM_prm_stElement_02_irv, ExM_prm_tEgRaw_09_irv, ExM_prm_pEgRaw_08_irv, ExM_prm_stElement_07_irv, ExM_prm_stNbTypElement_08_irv, ExM_prm_pEgRaw_05_irv, ExM_prm_stNbTypElement_07_irv, ExM_prm_tEgRaw_08_irv, ExM_prm_tEgRaw_03_irv, ExM_prm_pEgRaw_10_irv, ExM_prm_stElement_08_irv, ExM_prm_tEgRaw_07_irv, ExM_prm_pEgRaw_07_irv, ExM_prm_stElement_03_irv, ExM_prm_stNbTypElement_03_irv, ExM_prm_pEgRaw_03_irv, ExM_prm_tEgRaw_10_irv, ExM_prm_tEgRaw_12_irv, ExM_prm_pEgRaw_09_irv, ExM_mfTrbEstimSat_irv, ExM_prm_pEgRaw_12_irv, ExM_prm_pEgRaw_04_irv, ExM_prm_stNbTypElement_04_irv, ExM_prm_tEgRaw_06_irv, ExM_prm_pEgRaw_01_irv, ExM_prm_pEgRaw_02_irv], written-variable=[ExM_prm_pEgRaw_06_irv, ExM_prm_pEgRaw_11_irv, ExM_mfWgEstim_irv, ExM_prm_pEgRaw_08_irv, ExM_prm_pEgRaw_05_irv, ExM_prm_pEgRaw_10_irv, ExM_prm_pEgRaw_07_irv, ExM_prm_pEgRaw_03_irv, ExM_prm_pEgRaw_09_irv, ExM_mfTrbEstimSat_irv, ExM_prm_pEgRaw_12_irv, ExM_prm_pEgRaw_04_irv, ExM_prm_pEgRaw_01_irv, ExM_prm_pEgRaw_02_irv]
      10 x data receive point:
        dr_ExM_mfEgTot: data-element=R_ExM_mfEgTot.ExM_mfEgTot
        dr_ExM_prm_pEgFlt: data-element=R_ExM_prm_pEgFlt.ExM_prm_pEgFlt
        dr_Ext_nEng: data-element=R_Ext_nEng.Ext_nEng
        dr_InM_mfEGREstimEGRVlv: data-element=R_InM_mfEGREstimEGRVlv.InM_mfEGREstimEGRVlv
        dr_EngM_agCkOpInVlvEstimRef1: data-element=R_EngM_agCkOpInVlvEstimRef1.EngM_agCkOpInVlvEstimRef1
        dr_UsThrM_pAirExt: data-element=R_UsThrM_pAirExt.UsThrM_pAirExt
        dr_TrbAct_rOpTrbAct: data-element=R_TrbAct_rOpTrbAct.TrbAct_rOpTrbAct
        dr_ExM_pMes: data-element=R_ExM_pMes.ExM_pMes
        dr_EngM_agCkClsExVlvEstimRef1: data-element=R_EngM_agCkClsExVlvEstimRef1.EngM_agCkClsExVlvEstimRef1
        dr_ExM_mfEgWoutEGR: data-element=R_ExM_mfEgWoutEGR.ExM_mfEgWoutEGR
      8 x data send point:
        ds_ExM_pDsTrbEstimSI: data-element=P_ExM_pDsTrbEstimSI.ExM_pDsTrbEstimSI
        ds_ExM_rPresTrbEstimIvs: data-element=P_ExM_rPresTrbEstimIvs.ExM_rPresTrbEstimIvs
        ds_ExM_mfTrbEstimSat: data-element=P_ExM_mfTrbEstimSat.ExM_mfTrbEstimSat
        ds_ExM_rPresTrbEstim: data-element=P_ExM_rPresTrbEstim.ExM_rPresTrbEstim
        ds_ExM_mfWgEstim: data-element=P_ExM_mfWgEstim.ExM_mfWgEstim
        ds_ExM_prm_pEg: data-element=P_ExM_prm_pEg.ExM_prm_pEg
        ds_ExM_prm_pEgFlt: data-element=P_ExM_prm_pEgFlt.ExM_prm_pEgFlt
        ds_ExM_pExMnfEstim: data-element=P_ExM_pExMnfEstim.ExM_pExMnfEstim
      sync call ssp_FRM_bTrbAct: operation=R_FRM_bTrbAct.GetFunctionPermission
      sync call ssp_FRM_bSenPres: operation=R_FRM_bSenPres.GetFunctionPermission
  swc implementation Imp_ExMGslT2: code-generator=Real-Time Workshop Embedded Coder 5.5 (R2010a) 25-Jan-2010, programming-language=C, behavior=IB_ExMGslT2
    code-descriptors:
      code CodeDescriptor: type=SRC
        12 x xfile:
          ExMGslT2_types_h: url=ExMGslT2_types.h
          ExMGslT2_MemMap_h: url=ExMGslT2_MemMap.h
          ExMGslT2_h: url=ExMGslT2.h
          ExMGslT2_c: url=ExMGslT2.c
          ExMGslT2_import_h: url=ExMGslT2_import.h
          ExMGslT2_nvm_h: url=ExMGslT2_nvm.h
          ExMGslT2_nvm_c: url=ExMGslT2_nvm.c
          ExMGslT2_Def_c: url=ExMGslT2_Def.c
          ExMGslT2_Version_c: url=ExMGslT2_Version.c
          ExMGslT2_private_h: url=ExMGslT2_private.h
          ExMGslT2_Version_h: url=ExMGslT2_Version.h
          ExMGslT2_data_c: url=ExMGslT2_data.c
package /Components/SWC_ExMGslT2/ExMGslT2_IRVDatatypes
  16 x integer type, all with base-type=uint8, lower-limit=0, upper-limit=255:
    DT_ExM_prm_stElement_{01..08}_irv
    DT_ExM_prm_stNbTypElement_{01..08}_irv
  41 x real type, all with base-type=float32, allow-nan=false, encoding=SINGLE:
    DT_ExM_mfTrbEstimSat_irv
    DT_ExM_mfWgEstim_irv
    DT_ExM_prm_pEgRaw_{01..12}_irv
    DT_ExM_prm_tEgOxC_{01..03}_irv
    DT_ExM_prm_tEgRaw_{01..12}_irv
    DT_ExM_prm_tWall_{01..12}_irv
